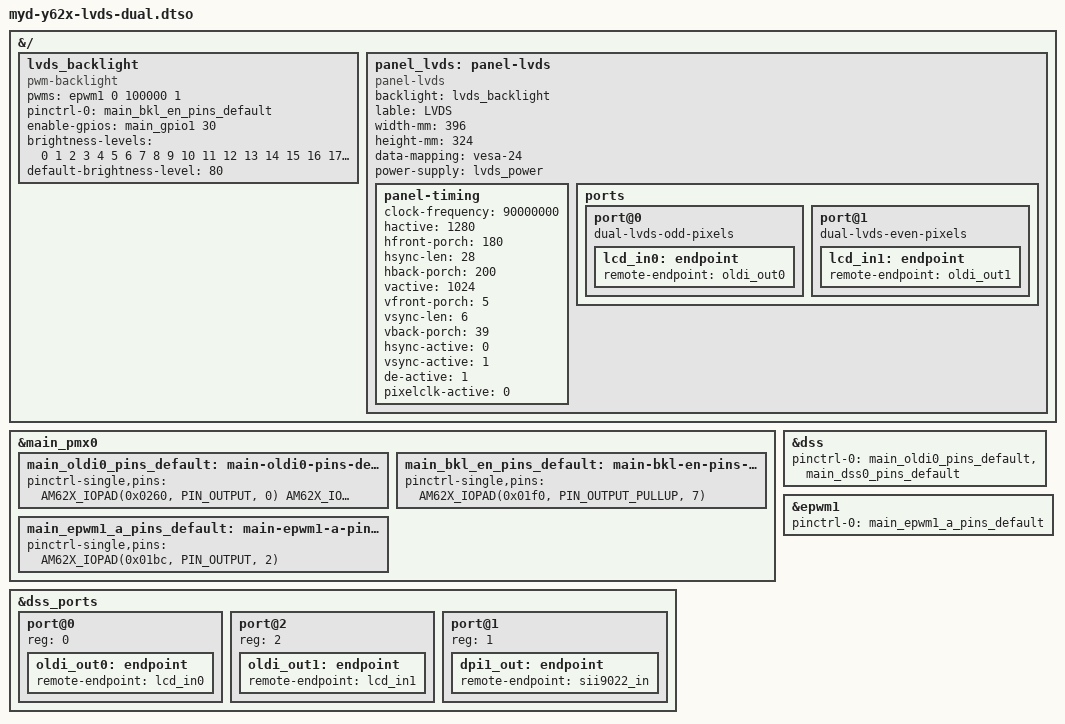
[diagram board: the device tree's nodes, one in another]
// SPDX-License-Identifier: GPL-2.0
/**
 * Microtips integrated OLDI panel and touch DT overlay for AM625 - SK
 *
 * Copyright (C) 2021 Texas Instruments Incorporated - http://www.ti.com/
 */

/dts-v1/;
/plugin/;
#include <dt-bindings/gpio/gpio.h>
#include <dt-bindings/interrupt-controller/irq.h>
#include "k3-pinctrl.h"

&{/} {


				lvds_backlight: lvds_backlight {
					compatible = "pwm-backlight";
					pwms = <&epwm1 0 100000 1>;
					status = "okay";
					pinctrl-names = "default";
					pinctrl-0 = <&main_bkl_en_pins_default>;
					enable-gpios = <&main_gpio1 30 GPIO_ACTIVE_HIGH>;
					brightness-levels = < 0  1  2  3  4  5  6  7  8  9
							     10 11 12 13 14 15 16 17 18 19
							     20 21 22 23 24 25 26 27 28 29
							     30 31 32 33 34 35 36 37 38 39
							     40 41 42 43 44 45 46 47 48 49
							     50 51 52 53 54 55 56 57 58 59
							     60 61 62 63 64 65 66 67 68 69
							     70 71 72 73 74 75 76 77 78 79
							     80 81 82 83 84 85 86 87 88 89
							     90 91 92 93 94 95 96 97 98 99
							    100>;
					default-brightness-level = <80>;
				};

			

				panel_lvds: panel-lvds {
					compatible = "panel-lvds";
					backlight = <&lvds_backlight>;
					lable = "LVDS";
					width-mm = <396>;
					height-mm = <324>;
					data-mapping = "vesa-24";
					power-supply = <&lvds_power>;

					panel-timing {
						clock-frequency = <90000000>;
						hactive = <1280>;
						hfront-porch = <180>;
						hsync-len = <28>;
						hback-porch = <200>;

						vactive = <1024>;
						vfront-porch = <5>;
						vsync-len = <6>;
						vback-porch = <39>;

						hsync-active = <0>;
						vsync-active = <1>;
						de-active = <1>;
						pixelclk-active = <0>;
					};

					ports {
						#address-cells = <1>;
						#size-cells = <0>;
						port@0 {
							dual-lvds-odd-pixels;
							lcd_in0: endpoint {
								remote-endpoint = <&oldi_out0>;
							};
						};

						port@1 {
							dual-lvds-even-pixels;
							lcd_in1: endpoint {
								remote-endpoint = <&oldi_out1>;
							};
						};
				
		
		};
	};
};

&main_pmx0 {
	main_oldi0_pins_default: main-oldi0-pins-default {
		pinctrl-single,pins = <
			AM62X_IOPAD(0x0260, PIN_OUTPUT, 0) /* (AA5) OLDI0_A0N */
			AM62X_IOPAD(0x025c, PIN_OUTPUT, 0) /* (Y6) OLDI0_A0P */
			AM62X_IOPAD(0x0268, PIN_OUTPUT, 0) /* (AD3) OLDI0_A1N */
			AM62X_IOPAD(0x0264, PIN_OUTPUT, 0) /* (AB4) OLDI0_A1P */
			AM62X_IOPAD(0x0270, PIN_OUTPUT, 0) /* (Y8) OLDI0_A2N */
			AM62X_IOPAD(0x026c, PIN_OUTPUT, 0) /* (AA8) OLDI0_A2P */
			AM62X_IOPAD(0x0278, PIN_OUTPUT, 0) /* (AB6) OLDI0_A3N */
			AM62X_IOPAD(0x0274, PIN_OUTPUT, 0) /* (AA7) OLDI0_A3P */
			AM62X_IOPAD(0x0280, PIN_OUTPUT, 0) /* (AC6) OLDI0_A4N */
			AM62X_IOPAD(0x027c, PIN_OUTPUT, 0) /* (AC5) OLDI0_A4P */
			AM62X_IOPAD(0x0288, PIN_OUTPUT, 0) /* (AE5) OLDI0_A5N */
			AM62X_IOPAD(0x0284, PIN_OUTPUT, 0) /* (AD6) OLDI0_A5P */
			AM62X_IOPAD(0x0290, PIN_OUTPUT, 0) /* (AE6) OLDI0_A6N */
			AM62X_IOPAD(0x028c, PIN_OUTPUT, 0) /* (AD7) OLDI0_A6P */
			AM62X_IOPAD(0x0298, PIN_OUTPUT, 0) /* (AD8) OLDI0_A7N */
			AM62X_IOPAD(0x0294, PIN_OUTPUT, 0) /* (AE7) OLDI0_A7P */
			AM62X_IOPAD(0x02a0, PIN_OUTPUT, 0) /* (AD4) OLDI0_CLK0N */
			AM62X_IOPAD(0x029c, PIN_OUTPUT, 0) /* (AE3) OLDI0_CLK0P */
			AM62X_IOPAD(0x02a8, PIN_OUTPUT, 0) /* (AE4) OLDI0_CLK1N */
			AM62X_IOPAD(0x02a4, PIN_OUTPUT, 0) /* (AD5) OLDI0_CLK1P */
		>;
	};

	main_bkl_en_pins_default: main-bkl-en-pins-default {
		pinctrl-single,pins = <
			AM62X_IOPAD(0x01f0, PIN_OUTPUT_PULLUP, 7) /* (A18) EXT_REFCLK1.GPIO1_30 */
		>;
	};

	main_epwm1_a_pins_default: main-epwm1-a-pins-default {
		pinctrl-single,pins = <
			AM62X_IOPAD(0x01bc, PIN_OUTPUT, 2) /* (A14) SPI0_CLK.EHRPWM1_A */
		>;
	};
};

&dss {
	pinctrl-names = "default";
	pinctrl-0 = <&main_oldi0_pins_default &main_dss0_pins_default>;
	status = "okay";
};

&dss_ports {
	#address-cells = <1>;
	#size-cells = <0>;

	/* VP1: LVDS Output (OLDI TX 0) */
	port@0 {
		reg = <0>;
		oldi_out0: endpoint {
			remote-endpoint = <&lcd_in0>;
		};
	};

	/* VP1: LVDS Output (OLDI TX 1) */
	port@2 {
		reg = <2>;
		oldi_out1: endpoint {
			remote-endpoint = <&lcd_in1>;
		};
	};

	port@1 {
		reg = <1>;

		dpi1_out: endpoint {
			remote-endpoint = <&sii9022_in>;
		};
	};
};

&epwm1 {
	pinctrl-names = "default";
	pinctrl-0 = <&main_epwm1_a_pins_default>;
	status = "okay";
};
